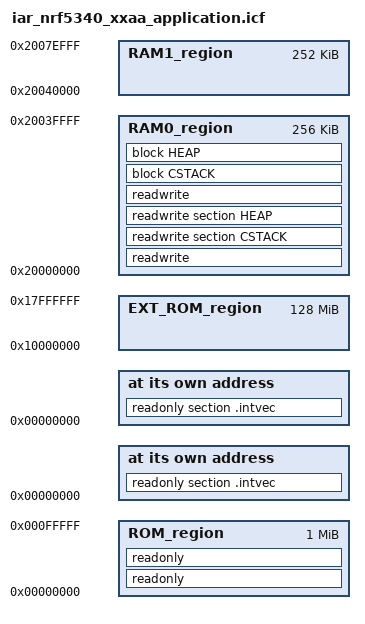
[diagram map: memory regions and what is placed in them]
/*###ICF### Section handled by ICF editor, don't touch! ****/
/*-Editor annotation file-*/
/* IcfEditorFile="$TOOLKIT_DIR$\config\ide\IcfEditor\cortex_v1_0.xml" */
/*-Specials-*/
define symbol __ICFEDIT_intvec_start__ = 0x00000000;
/*-Memory Regions-*/
define symbol __ICFEDIT_region_ROM_start__   = 0x00000000;
define symbol __ICFEDIT_region_ROM_end__     = 0x000FFFFF;
define symbol __ICFEDIT_region_EXT_ROM_start__   = 0x10000000;
define symbol __ICFEDIT_region_EXT_ROM_end__     = 0x17FFFFFF;
define symbol __ICFEDIT_region_RAM0_start__   = 0x20000000;
define symbol __ICFEDIT_region_RAM0_end__     = 0x2003FFFF;
define symbol __ICFEDIT_region_RAM1_start__   = 0x20040000;
define symbol __ICFEDIT_region_RAM1_end__     = 0x2007EFFF;

/*-Sizes-*/
define symbol __ICFEDIT_size_cstack__   = 0x4000;
define symbol __ICFEDIT_size_heap__     = 0x4000;
/**** End of ICF editor section. ###ICF###*/

define memory mem with size = 4G;
define region ROM_region = mem:[from __ICFEDIT_region_ROM_start__   to __ICFEDIT_region_ROM_end__];
define region EXT_ROM_region = mem:[from __ICFEDIT_region_EXT_ROM_start__   to __ICFEDIT_region_EXT_ROM_end__];
define region RAM0_region = mem:[from __ICFEDIT_region_RAM0_start__   to __ICFEDIT_region_RAM0_end__];
define region RAM1_region = mem:[from __ICFEDIT_region_RAM1_start__   to __ICFEDIT_region_RAM1_end__];


if (isdefinedsymbol(__STARTUP_CONFIG)) {

    /* CSTACK and HEAP sections defined in startup file. */
    keep { section CSTACK };
    keep { section HEAP };

    initialize by copy { readwrite };
    do not initialize  { section .noinit };
    do not initialize  { section CSTACK };
    do not initialize  { section HEAP };

    place at address mem:__ICFEDIT_intvec_start__ { readonly section .intvec };
    place in ROM_region   { readonly };
    place in RAM0_region   { readwrite, readwrite section CSTACK, readwrite section HEAP };

} else {

    define block CSTACK    with alignment = 8, size = __ICFEDIT_size_cstack__   { };
    define block HEAP      with alignment = 8, size = __ICFEDIT_size_heap__     { };

    initialize by copy { readwrite };
    do not initialize  { section .noinit };

    place at address mem:__ICFEDIT_intvec_start__ { readonly section .intvec };
    place in ROM_region   { readonly };
    place in RAM0_region   { readwrite, block CSTACK, block HEAP };

}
